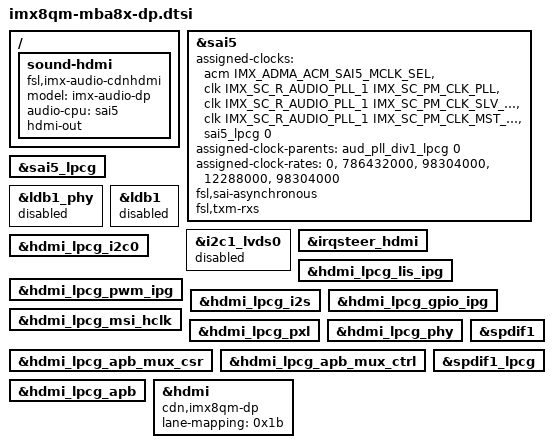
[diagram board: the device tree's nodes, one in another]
// SPDX-License-Identifier: (GPL-2.0-or-later OR MIT)
/*
 * Copyright 2019-2021 TQ-Systems GmbH
 */

/ {
	sound-hdmi {
		compatible = "fsl,imx-audio-cdnhdmi";
		model = "imx-audio-dp";
		audio-cpu = <&sai5>;
		hdmi-out;
	};
};

&sai5 {
	assigned-clocks = <&acm IMX_ADMA_ACM_SAI5_MCLK_SEL>,
			<&clk IMX_SC_R_AUDIO_PLL_1 IMX_SC_PM_CLK_PLL>,
			<&clk IMX_SC_R_AUDIO_PLL_1 IMX_SC_PM_CLK_SLV_BUS>,
			<&clk IMX_SC_R_AUDIO_PLL_1 IMX_SC_PM_CLK_MST_BUS>,
			<&sai5_lpcg 0>;
	assigned-clock-parents = <&aud_pll_div1_lpcg 0>;
	assigned-clock-rates = <0>, <786432000>, <98304000>, <12288000>, <98304000>;
	fsl,sai-asynchronous;
	fsl,txm-rxs;
	status = "okay";
};

&sai5_lpcg {
	status = "okay";
};

&ldb1_phy {
	status = "disabled";
};

&ldb1 {
	status = "disabled";
};

&i2c1_lvds0 {
	status = "disabled";
};

&irqsteer_hdmi {
	status = "okay";
};

&hdmi_lpcg_i2c0 {
	status = "okay";
};

&hdmi_lpcg_lis_ipg {
	status = "okay";
};

&hdmi_lpcg_pwm_ipg {
	status = "okay";
};

&hdmi_lpcg_i2s {
	status = "okay";
};

&hdmi_lpcg_gpio_ipg {
	status = "okay";
};

&hdmi_lpcg_msi_hclk {
	status = "okay";
};

&hdmi_lpcg_pxl {
	status = "okay";
};

&hdmi_lpcg_phy {
	status = "okay";
};

&hdmi_lpcg_apb_mux_csr {
	status = "okay";
};

&hdmi_lpcg_apb_mux_ctrl {
	status = "okay";
};

&hdmi_lpcg_apb {
	status = "okay";
};

&hdmi {
	compatible = "cdn,imx8qm-dp";
	lane-mapping = <0x1b>;
	status = "okay";
};

&spdif1 {
	status = "okay";
};

&spdif1_lpcg {
	status = "okay";
};
